# PRUSS1_IEP register map
Vendor: Texas Instruments
Peripheral module from a debugger description file (folder DRA72x).
Registers are 32-bit, read-write, reset 0x0 unless marked. A register's access mark holds for its fields unless they carry their own. Offsets are as the file gives them; lines under a group give offsets from that group; [hi:lo] are bit positions; {n}, {i} and the like mark numbered series; 'fields as' and 'values as' point back to an identical list; <NAME> marks a mode.

## PRUSS1_IEP
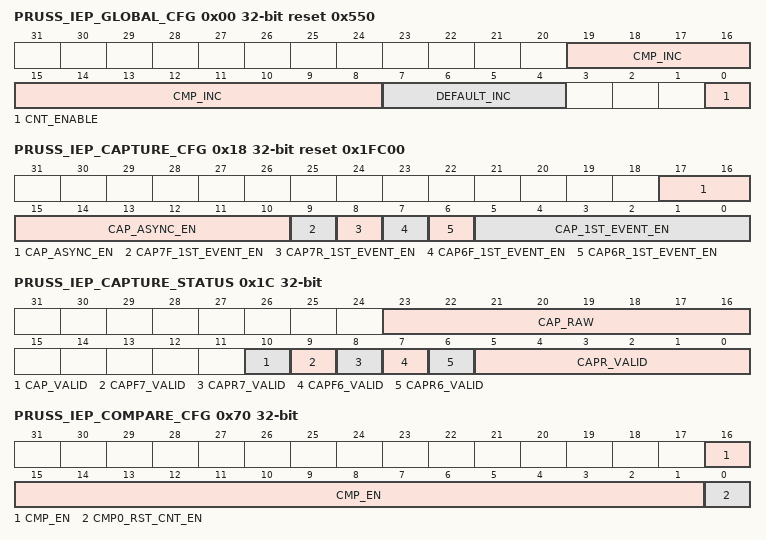
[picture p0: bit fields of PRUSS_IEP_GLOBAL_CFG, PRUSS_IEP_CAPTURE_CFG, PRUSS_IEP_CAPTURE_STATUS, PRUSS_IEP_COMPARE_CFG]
0x00 PRUSS_IEP_GLOBAL_CFG access per field reset 0x550 — GLOBAL CFG
  [19:8] CMP_INC rw — Defines the increment value when compensation is active
  [7:4] DEFAULT_INC rw — Defines the default increment value
  [0] CNT_ENABLE rw — Counter enable 0: Disables the counter. The counter maintains the current count. 1: Enables the counter.
0x04 PRUSS_IEP_STATUS access not given — STATUS
  [0] CNT_OVF — Counter overflow status. 0: No overflow 1: Overflow occurred (access RWr1Clr)
0x08 PRUSS_IEP_COMPENSATION access per field — COMPENSATION
  [23:0] COMPEN_CNT rw — Compensation counter. Read returns the current COMPEN_CNT value. 0: Compensation is disabled and counter will increment by DEFAULT_INC. n: Compensation is enabled until COMPEN_CNT decrements to 0. The COMPEN_CNT value decrements on every iep_clk cycle. When COMPEN_CNT is greater than 0, then count value increments by CMP_INC. NOTE: SLOW_COMPEN_CNT MUST be set to zero IF COMPEN_CNT is not.
0x0C PRUSS_IEP_SLOW_COMPENSATION — SLOW COMPENSATION
  [31:0] SLOW_COMPEN_CNT — Slow compensation counter. Write: 0x0: Slow compensation is disabled and counter will increment by DEFAULT_INC 0xn: Compensation is enabled for 1 count for every SLOW_COMPEN_CNT cycle, this is free running and continuous until software clears the MMR. For example, SLOW_COMPEN_CNT = 16, every 16 clock cycles the compensation value is used for 1 count. Note COMPEN_CNT MUST be set to zero IF SLOW_COMPEN_CNT is not zero. Read: Software can read the number of cycles left until the compensation event. For example, software writes SLOW_COMPEN_CNT = 0x100 and reads SLOW_COMPEN_CNT = 0x7. This means in 6 more IEP_CLK cycles before the counter reaches 0x1 for the compensation event. If software writes SLOW_COMPEN_CNT = 0x8000 before compensation event, then the counter will reset to 0x8000.
0x10 PRUSS_IEP_LOW_COUNTER — 64 bit count value low
  [31:0] COUNT — 64-bit count value (lower 32-bits). Increments by (DEFAULT_INC or CMP_INC) on every positive edge of PRUSS_IEP_CLK (200MHz) or PRUSS_GICLK.
0x14 PRUSS_IEP_HIGH_COUNTER — 64 bit count value high
  [31:0] COUNT — 64-bit count value (upper 32-bits). Increments by (DEFAULT_INC or CMP_INC) on every positive edge of PRUSS_IEP_CLK (200MHz) or PRUSS_GICLK.
0x18 PRUSS_IEP_CAPTURE_CFG access per field reset 0x1FC00 — CAPTURE CFG
  [17:10] CAP_ASYNC_EN rw — Synchronization of the capture inputs to the PRUSS_IEP_CLK/PRUSS_GICLK enable. Note if input capture signal is asynchronous to PRUSS_IEP_CLK, enabling synchronization will cause the capture contents to be invalid. CAP_ASYNC_EN[n] maps to CAPR[n]. 0: Disable synchronization 1: Enable synchronization
  [9] CAP7F_1ST_EVENT_EN rw — Capture 1st Event Enable for cap[7] fall 0: Continues mode. The capture status is not set when events occur. 1: First Event mode. The capture status is set when the first event occurs and must be cleared before new data will fill buffer. Time value is captured when first event occurs and held until time is read.
  [8] CAP7R_1ST_EVENT_EN rw — Capture 1-st Event Enable for cap[7] rise 0: Continues mode. The capture status is not set when events occur. 1: First Event mode. The capture status is set when the first event occurs and must be cleared before new data will fill buffer. Time value is captured when first event occurs and held until time is read.
  [7] CAP6F_1ST_EVENT_EN rw — Capture 1-st Event Enable for cap[6] fall 0: Continues mode. The capture status is not set when events occur. 1: First Event mode. The capture status is set when the first event occurs and must be cleared before new data will fill buffer. Time value is captured when first event occurs and held until time is read.
  [6] CAP6R_1ST_EVENT_EN rw — Capture 1-st Event Enable for cap[6] risev
  [5:0] CAP_1ST_EVENT_EN rw — Capture 1-st Event Enable for n 0: Continues mode. The capture status is not set when events occur. 1: First Event mode. The capture status is set when the first event occurs and must be cleared before new data will fill buffer. Time value is captured when first event occurs and held until time is read.
0x1C PRUSS_IEP_CAPTURE_STATUS ro — CAPTURE STATUS
  [23:16] CAP_RAW — Raw/Current status bit for each of the capture registers, where CAP_RAW[n] maps to CAPR[n]. 0: Current state is low for capn 1: Current state is high for capn
  [10] CAP_VALID — Valid status for capture function. Reflects the ORed result from CAP_STATUS [9:0]. 0: No Hit for any capture event, i.e., there are all 0 in CAP_STATUS [9:0]. 1: Hit for 1 or more captures events is pending, i.e., there has at least one value equal to 1 in CAP_STATUS [9:0].
  [9] CAPF7_VALID — Valid Status forPRUSS_IEP_CAPTURE_FALL07 0: No Hit, no capture event occurred 1: Hit, capture event occurred. Clear on read when its Capture Value is read CAP*_REG.
  [8] CAPR7_VALID — Valid Status forPRUSS_IEP_CAPTURE_RISE07 0: No Hit, no capture event occurred 1: Hit, capture event occurred. Clear on read when its Capture Value is read CAP*_REG.
  [7] CAPF6_VALID — Valid Status forPRUSS_IEP_CAPTURE_FALL06 0: No Hit, no capture event occurred 1: Hit, capture event occurred. Clear on read when its Capture Value is read CAP*_REG.
  [6] CAPR6_VALID — Valid Status forPRUSS_IEP_CAPTURE_RISE06 0: No Hit, no capture event occurred 1: Hit, capture event occurred. Clear on read when its Capture Value is read CAP*_REG.
  [5:0] CAPR_VALID — Valid Status capr_validn maps PRUSS_IEP_CAPRn_REG, where n=0 to 5, 0: No Hit, no capture event occurred 1: Hit, capture event occurred. Clear on read when its Capture Value is read CAP*_REG.
{0x20+8i} PRUSS_IEP_CAPTURE_RISE0i_{i} ro (i=0..5) — CAPTURE RISE(i) low
  [31:0] CAPR — Capture Value for capture rise i event low
{0x24+8i} PRUSS_IEP_CAPTURE_RISE1i_{i} ro (i=0..5) — CAPTURE RISE(i) high
  [31:0] CAPR — Capture Value for capture rise i event high
0x50 PRUSS_IEP_CAPTURE_RISE06 ro — CAPTURE RISE6 low
  [31:0] CAPR — Capture Value for capr6 (rise) event low
0x54 PRUSS_IEP_CAPTURE_RISE16 ro — CAPTURE RISE6 high
  [31:0] CAPR — Capture Value for capr6 (rise) event high
0x58 PRUSS_IEP_CAPTURE_FALL06 ro — CAPTURE FALL6 low
  [31:0] CAPF — Capture Value for capf6 (fall) event low
0x5C PRUSS_IEP_CAPTURE_FALL16 ro — CAPTURE FALL6 high
  [31:0] CAPF — Capture Value for capf6 (fall) event high
0x60 PRUSS_IEP_CAPTURE_RISE07 ro — CAPTURE RISE7 low
  [31:0] CAPR — Capture Value for capr7 (rise) event low
0x64 PRUSS_IEP_CAPTURE_RISE17 ro — CAPTURE RISE7 high
  [31:0] CAPR — Capture Value for capr7 (rise) event high
0x68 PRUSS_IEP_CAPTURE_FALL07 ro — CAPTURE FALL7 low
  [31:0] CAPF — Capture Value for capf7 (fall) event low
0x6C PRUSS_IEP_CAPTURE_FALL17 ro — CAPTURE FALL7 high
  [31:0] CAPF — Capture Value for capf7 (fall) event high
0x70 PRUSS_IEP_COMPARE_CFG access per field — COMPARE CFG
  [16:1] CMP_EN rw — Enable bits for each of the compare registers CMP_EN =0 : Disables CMPj/k Event CMP_EN=1: Enables CMPj/k Event CMP_EN[0] (bit 1 of register) maps to CMP0 event
  [0] CMP0_RST_CNT_EN rw — Enable the reset of the counter 0: Disable 1: Enable the reset of the counter if a CMP0 event occurs
0x74 PRUSS_IEP_COMPARE_STATUS access not given — COMPARE STATUS
  [15:0] CMP_HIT — Status bit for each of the compare registers 'Match' indicates the current counter is greater than or equal to the compare value. Note it is the firmware's responsibility to handle the IEP overflow. CMP_HIT&lt;n&gt; = 0: No match has occured CMP_HIT&lt;n&gt; = 1: A match occured. The associated hardware event signal will assert and remain high until the status is cleared. (access RWr1Clr)
{0x78+8i} PRUSS_IEP_COMPARE0j_{i} (i=0..7) — COMPARE(j) low
  [31:0] CMP — Compare j low value
{0x7C+8i} PRUSS_IEP_COMPARE1j_{i} (i=0..7) — COMPARE(j) high
  [31:0] CMP — Compare j high value
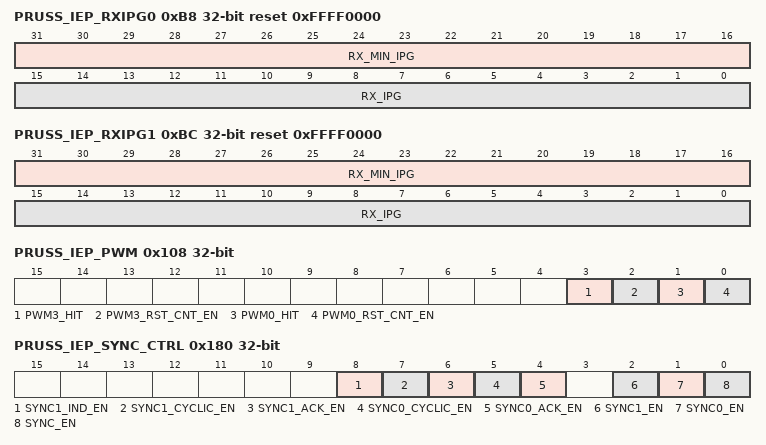
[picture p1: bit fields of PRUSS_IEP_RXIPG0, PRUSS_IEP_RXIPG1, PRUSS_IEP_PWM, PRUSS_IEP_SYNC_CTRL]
0xB8 PRUSS_IEP_RXIPG0 access per field reset 0xFFFF0000 — RXIPG0 This register can be used to determine the last RX IPG and the smallest RX IPG. RXIPG0 is the status for the RX port which is attached to PRU0.
  [31:16] RX_MIN_IPG rw — Defines the current minimum number of PRUSS_GICLK/PRUSS_IEP_CLK cycles that is RXDV is sampled low. It stores the current smallest RX_IPG Read: The value can be read at any time. It gets updated after RX_IPG update if RX_MIN_IPG &gt; RX_IPG. Write:Any write will reset this bitfield to 0xffff
  [15:0] RX_IPG ro — Records the current number of PRUSS_GICLK/PRUSS_IEP_CLK cycles that RXDV is sampled low. Value is updated after RX_DV transitions from low to high. It will saturate at 0xffff.
0xBC PRUSS_IEP_RXIPG1 access per field reset 0xFFFF0000 — RXIPG1This register can be used to determine the last RX IPG and the smallest RX IPG. RXIPG1 is the status for the RX port which is attached to PRU1
  fields as PRUSS_IEP_RXIPG0
{0xC0+8i} PRUSS_IEP_COMPARE0k_{i} (i=8..15) — COMPARE(k) low
  [31:0] CMP — Compare k low value
0x100 PRUSS_IEP_LOW_COUNTER_RESET_VALUE — LOW_COUNTER_RESET_VALUE
  [31:0] RESET_VAL — Reset value (lower 32-bits). This register enables SW to define the reset state of the Master Counter, which can be reset by the following events (if enabled): CMP0 event; PWM0_SYNC_OUT event; PWM3_SYNC_OUT event. The RESET_VAL should be in increments of the DEFAULT_INC (default state is 5). For example, 0x0000_000A.
{0xC4+8i} PRUSS_IEP_COMPARE1k_{i} (i=8..15) — COMPARE(k) high
  [31:0] CMP — Compare k high value
0x104 PRUSS_IEP_HIGH_COUNTER_RESET_VALUE — HIGH_COUNTER_RESET_VALUE
  [31:0] RESET_VAL — Reset value (upper 32-bits). This register enables SW to define the reset state of the Master Counter, which can be reset by the following events (if enabled): CMP0 event; PWM0_SYNC_OUT event; PWM3_SYNC_OUT event. The RESET_VAL should be in increments of the DEFAULT_INC (default state is 5). For example, 0x0000_000A.
0x108 PRUSS_IEP_PWM access not given — PWM Sync Out
  [3] PWM3_HIT — The raw status bit of pwm3_sync_out event. 0x0: No pwm3_sync_out event 0x1: pwm3_sync_out event occurred Write 1 to Clear. (access RW1Clr)
  [2] PWM3_RST_CNT_EN rw — Enable the reset of the counter by a pwm3_sync_out event. 0x0: Disable 0x1: Enable the reset of the counter if a pwm3_sync_out event occurs
  [1] PWM0_HIT — The raw status bit of pwm0_sync_out event. 0x0: No pwm0_sync_out event 0x1: pwm0_sync_out event occurred Write 1 to Clear (access RW1Clr)
  [0] PWM0_RST_CNT_EN rw — Enable the reset of the counter by a pwm0_sync_out event. 0x0: Disable 0x1: Enable the reset of the counter if a pwm0_sync_out event occurs
0x180 PRUSS_IEP_SYNC_CTRL access per field — SYNC CTRL
  [8] SYNC1_IND_EN rw — SYNC1 independent mode enable. Independent mode means the SYNC1 signal can be different from SYNC0. 0h: Dependent mode 1h: Independent mode
  [7] SYNC1_CYCLIC_EN rw — SYNC1 single shot or cyclic/auto generation mode enable 0h: Disable, single shot mode 1h: Enable, cyclic generation mode
  [6] SYNC1_ACK_EN rw — SYNC1 acknowledgement mode enable 0h: Disable, SYNC1 will go low after pulse width is met. 1h: Enable, SYNC1 will remain asserted until receiving software acknowledges by reading PRUSS_IEP_SYNC1_STAT which clears on read.
  [5] SYNC0_CYCLIC_EN rw — SYNC0 single shot or cyclic/auto generation mode enable 0h: Disable, single shot mode 1h: Enable, cyclic generation mode
  [4] SYNC0_ACK_EN rw — SYNC0 acknowledgement mode enable 0h: Disable, SYNC0 will go low after pulse width is met. 1h: Enable, SYNC0 will remain asserted until receiving software acknowledges by reading PRUSS_IEP_SYNC0_STAT which clears on read.
  [2] SYNC1_EN rw — SYNC1 generation enable 0: Disable SYNC1 generation. If SYNC1 is low, it will stop immediately. If SYNC1 is high, it will stop after SYNC1 goes low. 1: Enable SYNC1 generation
  [1] SYNC0_EN rw — SYNC0 generation enable 0: Disable SYNC0 generation. If SYNC0 is low, it will stop immediately. If SYNC0 is high, it will stop after SYNC0 goes low. 1: Enable SYNC0 generation
  [0] SYNC_EN rw — SYNC generation enable 0: Disable the generation and clocking of SYNC0 and SYNC1 logic. If SYNC0 AND SYNC1 is low, it will stop immediately. If SYNC0 OR SYNC1 is high, it will stop after SYCN0 AND SYNC1 goes low. Note that you might get 1 extra high pulse if this is disabled during a high pulse of one and the 2nd pulse goes high before the last pulse low if you do not de-assert sync0_en and sync1_en at the same time. SW should always de-assert both sync1_en and sync0_en at the same time as sync_en is de-asserted 1: Enables SYNC0 and SYNC1 generation
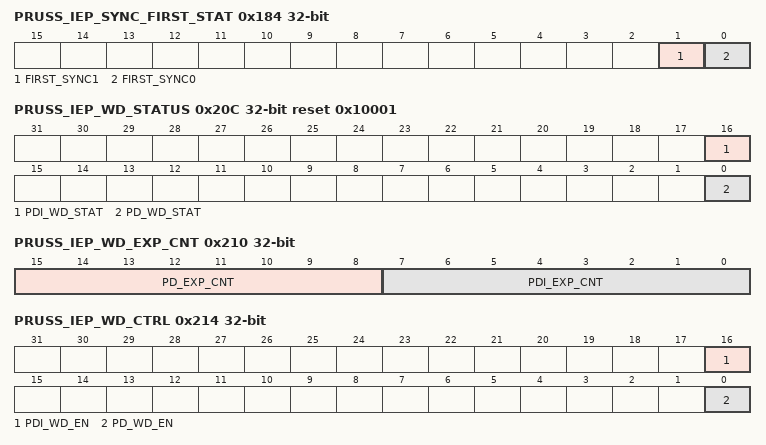
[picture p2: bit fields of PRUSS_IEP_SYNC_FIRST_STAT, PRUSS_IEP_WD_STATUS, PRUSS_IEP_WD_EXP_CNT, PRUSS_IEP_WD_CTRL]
0x184 PRUSS_IEP_SYNC_FIRST_STAT ro — SYNC CTRL
  [1] FIRST_SYNC1 — SYNC1 First Event status 0: SYNC1 first event has not occurred 1: SYNC1 first event has occurred. This bits is cleared when sync1_en = 0
  [0] FIRST_SYNC0 — SYNC0 First Event status 0: SYNC0 first event has not occurred 1: SYNC0 first event has occurred. This bits is cleared when sync0_en = 0
0x188 PRUSS_IEP_SYNC0_STAT access not given — SYNC CTRL
  [0] SYNC0_PEND — SYNC0 pending state 0: SYNC0 is not pending 1: SYNC0 is pending or has occurred when SYNC0_ACK_EN = 0 (Disable). Write '1' to clear. (access RWr1Clr)
0x18C PRUSS_IEP_SYNC1_STAT access not given — SYNC CTRL
  [0] SYNC1_PEND — SYNC1 pending state 0: SYNC1 is not pending 1 SYNC1 is pending or has occurred when SYNC1_ACK_EN = 0 (Disable). Write '1' to Clear. (access RWr1Clr)
0x190 PRUSS_IEP_SYNC_PWIDTH — SYNC CTRL
  [31:0] SYNC_HPW — Defines the number of clock cycles SYNC0/1 will be high. Note if SYNC0/1 is disabled during pulse width time (that is, SYNC_CTRL[SYNC0_EN | SYNC1_EN | SYNC_EN] = 0), the ongoing pulse will be terminated. 0x0 : 1 clock cycle. 0x1 : 2 clock cycles. N : N+1 clock cycles.
0x194 PRUSS_IEP_SYNC0_PERIOD reset 0x1 — SYNC CTRL
  [31:0] SYNC0_PERIOD — Defines the period between the rising edges of SYNC0. 0x0: Reserved 0x1: 2 clk cycles period N: N+1 clk cycles period
0x198 PRUSS_IEP_SYNC1_DELAY — SYNC CTRL
  [31:0] SYNC1_DELAY — When SYNC1_IND_EN = 0, defines number of clock cycles from the start of SYNC0 to the start of SYNC1. Note this is the delay before the start of SYNC1. 0h: No delay 1h: 1 clock cycle delay. Nh: N clock cycles delay. When SYNC1_IND_EN = 1, defines the period between the rising edges of SYNC1. 0h: Reserved. 1h: 2 clock cycles period. Nh: N+1 clock cycles period
0x19C PRUSS_IEP_SYNC_START — SYNC CTRL
  [31:0] SYNC_START — Defines the start time after the activation event. 0h: 1 clock cycle delay. Nh: N+1 clock cycles delay.
0x200 PRUSS_IEP_WD_PREDIV access per field reset 0x4E20 — WD
  [15:0] PRE_DIV rw — Defines the number of iep_clk cycles per WD clock event. Note that the WD clock is a free-running clock. The value 0x4e20 (or 20000) generates a rate of 100 us if iep_clk is 200 MHz. seconds/(WD event) = (clock cycles per WD event)/(clock cycles per second) = 20000/(200 x [10]^6 ) = 100 us
0x204 PRUSS_IEP_PDI_WD_TIM access per field reset 0x3E8 — WD
  [15:0] PDI_WD_TIME rw — Defines the number of WD ticks (or increments) for PDI WD, that is, the number of WD increments. If PRE_DIV is set to 100 us, then the value 0x03e8 (or 1000) provides a rate of 100ms. Read returns the current count. Counter is reset by software write to register or when Digital Data In capture occurs. WD is disabled if WD time is set to 0x0. Note when an expiration event occurs, the expiration counter (PDI_EXP_CNT) increments and status (PDI_WD_STAT) clears.
0x208 PRUSS_IEP_PD_WD_TIM access per field reset 0x3E8 — WD
  [15:0] PD_WD_TIME rw — Defines the number of WD ticks (or increments) for PDI WD, that is, the number of WD increments. If PRE_DIV is set to 100 us, then 0x03e8 (or 1000) provides a rate of 100ms. Read returns the current count. Counter is reset by software write to register or every write access to Sync Managers with WD trigger enable bit set. WD is disabled if WD time is set to 0x0. Expiration actions: Increment expiration counter, clear status. Digital Data out forced to zero if pr1_edio_oe_ext = 1 and DIGIO_EXT.SW_DATA_OUT_UPDATE = 0.
0x20C PRUSS_IEP_WD_STATUS ro reset 0x10001 — WD
  [16] PDI_WD_STAT — WD PDI status. 0h: Expired (PDI_WD_EXP event generated) 1h: Active or disabled
  [0] PD_WD_STAT — WD PD status (triggered by Sync Mangers status). 0h: Expired (PD_WD_EXP event generated) 1h: Active or disabled
0x210 PRUSS_IEP_WD_EXP_CNT access not given — WD
  [15:8] PD_EXP_CNT — WD PD expiration counter. Counter increments on every PD time out and stops at FFh (access RWrClr)
  [7:0] PDI_EXP_CNT — WD PDI expiration counter. Counter increments on every PDI time out and stops at FFh. (access RWrClr)
0x214 PRUSS_IEP_WD_CTRL access per field — WD
  [16] PDI_WD_EN rw — Watchdog PDI 0: Disable 1: Enable
  [0] PD_WD_EN rw — Watchdog PD 0: Disable 1: Enable
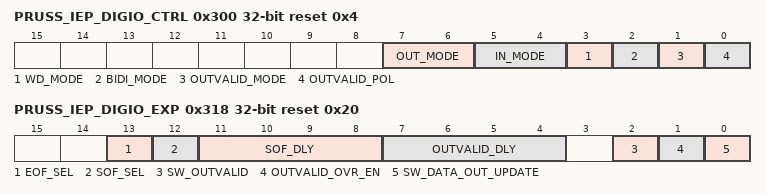
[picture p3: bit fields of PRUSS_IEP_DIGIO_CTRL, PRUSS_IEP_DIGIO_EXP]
0x300 PRUSS_IEP_DIGIO_CTRL access per field reset 0x4 — DIGIO
  [7:6] OUT_MODE rw — Defines event that triggers data out to be updated. Note if OUTVALID_MODE is set, then data out is forced to zero if a WD PD expiration occurs (PD_WD_EXP) from the WD block and pr1_edio_oe_ext = 1. 0: PRU0/1_RX_EOF 1: Reserved 2: DC SYNC0 event 3: DC SYNC1 event
  [5:4] IN_MODE rw — Defines event that triggers data in to be sampled 0b00: PRU0/1_RX_SOF 0b01: Rising edge of external pr&lt;k&gt;-edio_latch_in signal 0b10: DC rising edge of SYNC0 event 0b11: DC rising edge of SYNC1 event
  [3] WD_MODE rw — Defines Watchdog behavior 0: Outputs are reset immediately after watchdog expires 1: Outputs are reset with next output event that follows watchdog expiration
  [2] BIDI_MODE ro — Indicates the digital input/output direction. DUE TO INTEGRATION, ACTUAL MODE IS UNIDIRECTIONAL IN THIS DEVICE. 0: Unidirectional mode: input/output direction of pins configured individually 1: Bidirectional mode: all I/O pins are bidirectional, direction configuration is ignored
  [1] OUTVALID_MODE rw — Defines OUTVALID mode 0: Output event signaling 1: Output data is updated if watchdog is triggered. Output data is forced to zero if PD_WD_EXP from the WD block and pr1_edio_oe_ext = 1
  [0] OUTVALID_POL ro — Indicates OUTVALID polarity 0: Active High 1: Active Low
0x308 PRUSS_IEP_DIGIO_DATA_IN ro reset not defined — DIGIO
  [31:0] DATA_IN — Data input. Digital inputs can be configured to be sampled in four ways. 1: Digital inputs are sampled at the start of each frame. The SOF signal can be used externally to update the input data, because the SOF is signaled before input data is sampled. 2: The sample time can be controlled externally by using the pr1_edio_latch_in signal. 3: Digital inputs are sampled at SYNC0 events. 4: Digital inputs are sampled at SYNC1 events. These can be configured by PRUSS_IEP_DIGIO_CTRL[5:4] IN_MODE. Only [7:0] are exported to device pins in this device.
0x30C PRUSS_IEP_DIGIO_DATA_IN_RAW ro reset not defined — DIGIO
  [31:0] DATA_IN_RAW — Raw Data Input. Direct sample of EDIO_DATA_IN[31:0]. Only [7:0] are exported to device pins in this device.
0x310 PRUSS_IEP_DIGIO_DATA_OUT — DIGIO
  [31:0] DATA_OUT — Data output. Digital outputs can be configured to be updated in four ways. 1: Digital outputs are updated at the end of each frame (EOF mode). 2: Digital outputs are updated with SYNC0 events 3: Digital outputs are updated SYNC1events. 4: Digital outputs are updated at the end of a frame which triggered the Process Data Watchdog. Digital Outputs are only updated if the frame was correct (WD_TRIG mode). These can be configured by out_mode.
0x314 PRUSS_IEP_DIGIO_DATA_OUT_EN — DIGIO
  [31:0] DATA_OUT_EN — Enables tri-state control for pr&lt;k&gt;_edio_data_out[7:0].
0x318 PRUSS_IEP_DIGIO_EXP access per field reset 0x20 — DIGIO
  [13] EOF_SEL rw — Defines which RX_EOF is used for PR1_EDIO_DATA_IN[31:0] capture 0: PRU0_RX_EOF 1: PRU1_RX_EOF
  [12] SOF_SEL rw — Defines which RX_SOF is used for PR1_EDIO_DATA_IN[31:0] capture 0: PRU0_RX_SOF 1: PRU1_RX_SOF
  [11:8] SOF_DLY rw — Define the number of iep_clk (PRUSS_IEP_CLK) cycle delay of SOF PR1_EDIO_DATA_IN[31:0] capture
  [7:4] OUTVALID_DLY rw — Define the number of iep_clk (PRUSS_IEP_CLK) cycle delay on assertion of PR1_EDIO_OUTVALID. Min is 2 clock cycles. Max is 16 clock cycles
  [2] SW_OUTVALID rw — pr1_edio_outvalid = SW_OUTVALID, only if OUTVALID_OVR_EN is set.
  [1] OUTVALID_OVR_EN rw — Enable software to control value of pr&lt;k&gt;_edio_data_out[7:0] 0: Disable 1: Enable
  [0] SW_DATA_OUT_UPDATE rw — Defines the value of pr1_edio_data_out when OUTVALID_OVR_EN = 1. Read 1: Start bit event occurred Read 0: Start bit event has not occurred Write 1: pr1_edio_data_out by software data out. Write 0: No Effect
